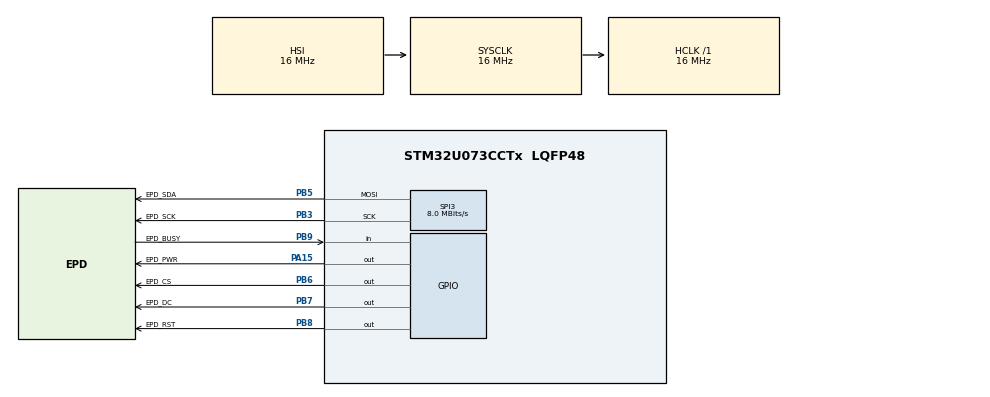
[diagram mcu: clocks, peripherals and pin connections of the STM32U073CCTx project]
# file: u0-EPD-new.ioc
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Mcu.Family=STM32U0
Mcu.Name=STM32U073CCTx
Mcu.Package=LQFP48
NVIC.PriorityGroup=NVIC_PRIORITYGROUP_2
PA13\ (SWDIO).GPIO_Label=SWDIO
PA13\ (SWDIO).Mode=Serial_Wire
PA13\ (SWDIO).Signal=DEBUG_JTMS-SWDIO
PA14\ (SWCLK).GPIO_Label=SWCLK
PA14\ (SWCLK).Mode=Serial_Wire
PA14\ (SWCLK).Signal=DEBUG_JTCK-SWCLK
PA15.GPIO_Label=EPD_PWR
PA15.Signal=GPIO_Output
PB3.GPIO_Label=EPD_SCK
PB3.GPIO_Speed=GPIO_SPEED_FREQ_HIGH
PB3.Mode=TX_Only_Simplex_Unidirect_Master
PB3.Signal=SPI3_SCK
PB5.GPIO_Label=EPD_SDA
PB5.GPIO_Speed=GPIO_SPEED_FREQ_HIGH
PB5.Mode=TX_Only_Simplex_Unidirect_Master
PB5.Signal=SPI3_MOSI
PB6.GPIO_Label=EPD_CS
PB6.Signal=GPIO_Output
PB7.GPIO_Label=EPD_DC
PB7.Signal=GPIO_Output
PB8.GPIO_Label=EPD_RST
PB8.Signal=GPIO_Output
PB9.GPIO_Label=EPD_BUSY
PB9.Signal=GPIO_Input
ProjectManager.HeapSize=0x200
ProjectManager.StackSize=0x400
ProjectManager.TargetToolchain=STM32CubeIDE
RCC.AHBFreq_Value=16000000
RCC.CortexFreq_Value=16000000
RCC.HCLKFreq_Value=16000000
RCC.HSE_VALUE=4000000
RCC.HSI48_VALUE=48000000
RCC.HSI_VALUE=16000000
RCC.LSE_VALUE=32768
RCC.MSI_VALUE=4000000
RCC.SYSCLKFreq_VALUE=16000000
RCC.VCOOutputFreq_Value=64000000
SPI3.BaudRatePrescaler=SPI_BAUDRATEPRESCALER_2
SPI3.CalculateBaudRate=8.0 MBits/s
SPI3.DataSize=SPI_DATASIZE_8BIT
SPI3.Direction=SPI_DIRECTION_2LINES
SPI3.Mode=SPI_MODE_MASTER
SPI3.NSSPMode=SPI_NSS_PULSE_DISABLE
SPI3.VirtualNSS=VM_NSSHARD
SPI3.VirtualType=VM_MASTER
VP_PWR_VS_SECSignals.Mode=Security/Privilege
board=custom

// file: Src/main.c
/* USER CODE BEGIN Header */
/**
  ******************************************************************************
  * @file           : main.c
  * @brief          : Main program body
  ******************************************************************************
  * @attention
  *
  * Copyright (c) 2026 STMicroelectronics.
  * All rights reserved.
  *
  * This software is licensed under terms that can be found in the LICENSE file
  * in the root directory of this software component.
  * If no LICENSE file comes with this software, it is provided AS-IS.
  *
  ******************************************************************************
  */
/* USER CODE END Header */
#include "main.h"

/* USER CODE BEGIN Includes */
#include "GDEY037T03.h"
/* USER CODE END Includes */

SPI_HandleTypeDef hspi3;

void SystemClock_Config(void);
static void MX_GPIO_Init(void);
static void MX_SPI3_Init(void);

int main(void)
{

  /* MCU Configuration--------------------------------------------------------*/

  /* Reset of all peripherals, Initializes the Flash interface and the Systick. */
  HAL_Init();

  /* Configure the system clock */
  SystemClock_Config();

  /* Initialize all configured peripherals */
  MX_GPIO_Init();
  MX_SPI3_Init();
  /* USER CODE BEGIN 2 */
  EPD_wakeup(&hspi3);

  EPD_set_border(&hspi3, BORDER_WHITE);
  EPD_fill_screen(&hspi3, WHITE);
  EPD_refresh(&hspi3);

  EPD_deepsleep(&hspi3);
  /* USER CODE END 2 */

  /* Infinite loop */
  while (1)
  {

  }
}

void SystemClock_Config(void)
{
  RCC_OscInitTypeDef RCC_OscInitStruct = {0};
  RCC_ClkInitTypeDef RCC_ClkInitStruct = {0};

  /** Configure the main internal regulator output voltage
  */
  HAL_PWREx_ControlVoltageScaling(PWR_REGULATOR_VOLTAGE_SCALE2);

  /** Initializes the RCC Oscillators according to the specified parameters
  * in the RCC_OscInitTypeDef structure.
  */
  RCC_OscInitStruct.OscillatorType = RCC_OSCILLATORTYPE_HSI;
  RCC_OscInitStruct.HSIState = RCC_HSI_ON;
  RCC_OscInitStruct.HSICalibrationValue = RCC_HSICALIBRATION_DEFAULT;
  RCC_OscInitStruct.PLL.PLLState = RCC_PLL_NONE;
  if (HAL_RCC_OscConfig(&RCC_OscInitStruct) != HAL_OK)
  {
    Error_Handler();
  }

  /** Initializes the CPU, AHB and APB buses clocks
  */
  RCC_ClkInitStruct.ClockType = RCC_CLOCKTYPE_HCLK|RCC_CLOCKTYPE_SYSCLK
                              |RCC_CLOCKTYPE_PCLK1;
  RCC_ClkInitStruct.SYSCLKSource = RCC_SYSCLKSOURCE_HSI;
  RCC_ClkInitStruct.AHBCLKDivider = RCC_SYSCLK_DIV1;
  RCC_ClkInitStruct.APB1CLKDivider = RCC_HCLK_DIV1;

  if (HAL_RCC_ClockConfig(&RCC_ClkInitStruct, FLASH_LATENCY_1) != HAL_OK)
  {
    Error_Handler();
  }
}

static void MX_SPI3_Init(void)
{

  /* SPI3 parameter configuration*/
  hspi3.Instance = SPI3;
  hspi3.Init.Mode = SPI_MODE_MASTER;
  hspi3.Init.Direction = SPI_DIRECTION_2LINES;
  hspi3.Init.DataSize = SPI_DATASIZE_8BIT;
  hspi3.Init.CLKPolarity = SPI_POLARITY_LOW;
  hspi3.Init.CLKPhase = SPI_PHASE_1EDGE;
  hspi3.Init.NSS = SPI_NSS_SOFT;
  hspi3.Init.BaudRatePrescaler = SPI_BAUDRATEPRESCALER_2;
  hspi3.Init.FirstBit = SPI_FIRSTBIT_MSB;
  hspi3.Init.TIMode = SPI_TIMODE_DISABLE;
  hspi3.Init.CRCCalculation = SPI_CRCCALCULATION_DISABLE;
  hspi3.Init.CRCPolynomial = 7;
  hspi3.Init.CRCLength = SPI_CRC_LENGTH_DATASIZE;
  hspi3.Init.NSSPMode = SPI_NSS_PULSE_DISABLE;
  if (HAL_SPI_Init(&hspi3) != HAL_OK)
  {
    Error_Handler();
  }

}

static void MX_GPIO_Init(void)
{
  GPIO_InitTypeDef GPIO_InitStruct = {0};

  /* GPIO Ports Clock Enable */
  __HAL_RCC_GPIOC_CLK_ENABLE();
  __HAL_RCC_GPIOF_CLK_ENABLE();
  __HAL_RCC_GPIOA_CLK_ENABLE();
  __HAL_RCC_GPIOB_CLK_ENABLE();

  /*Configure GPIO pin Output Level */
  HAL_GPIO_WritePin(EPD_PWR_GPIO_Port, EPD_PWR_Pin, GPIO_PIN_RESET);

  /*Configure GPIO pin Output Level */
  HAL_GPIO_WritePin(GPIOB, EPD_CS_Pin|EPD_DC_Pin|EPD_RST_Pin, GPIO_PIN_RESET);

  /*Configure GPIO pins : PC13 PC14 PC15 */
  GPIO_InitStruct.Pin = GPIO_PIN_13|GPIO_PIN_14|GPIO_PIN_15;
  GPIO_InitStruct.Mode = GPIO_MODE_ANALOG;
  GPIO_InitStruct.Pull = GPIO_NOPULL;
  HAL_GPIO_Init(GPIOC, &GPIO_InitStruct);

  /*Configure GPIO pins : PF0 PF1 PF2 PF3 */
  GPIO_InitStruct.Pin = GPIO_PIN_0|GPIO_PIN_1|GPIO_PIN_2|GPIO_PIN_3;
  GPIO_InitStruct.Mode = GPIO_MODE_ANALOG;
  GPIO_InitStruct.Pull = GPIO_NOPULL;
  HAL_GPIO_Init(GPIOF, &GPIO_InitStruct);

  /*Configure GPIO pins : PA0 PA1 PA2 PA3
                           PA4 PA5 PA6 PA7
                           PA8 PA9 PA10 PA11
                           PA12 */
  GPIO_InitStruct.Pin = GPIO_PIN_0|GPIO_PIN_1|GPIO_PIN_2|GPIO_PIN_3
                          |GPIO_PIN_4|GPIO_PIN_5|GPIO_PIN_6|GPIO_PIN_7
                          |GPIO_PIN_8|GPIO_PIN_9|GPIO_PIN_10|GPIO_PIN_11
                          |GPIO_PIN_12;
  GPIO_InitStruct.Mode = GPIO_MODE_ANALOG;
  GPIO_InitStruct.Pull = GPIO_NOPULL;
  HAL_GPIO_Init(GPIOA, &GPIO_InitStruct);

  /*Configure GPIO pins : PB0 PB1 PB2 PB10
                           PB11 PB12 PB13 PB14
                           PB15 PB4 */
  GPIO_InitStruct.Pin = GPIO_PIN_0|GPIO_PIN_1|GPIO_PIN_2|GPIO_PIN_10
                          |GPIO_PIN_11|GPIO_PIN_12|GPIO_PIN_13|GPIO_PIN_14
                          |GPIO_PIN_15|GPIO_PIN_4;
  GPIO_InitStruct.Mode = GPIO_MODE_ANALOG;
  GPIO_InitStruct.Pull = GPIO_NOPULL;
  HAL_GPIO_Init(GPIOB, &GPIO_InitStruct);

  /*Configure GPIO pin : EPD_PWR_Pin */
  GPIO_InitStruct.Pin = EPD_PWR_Pin;
  GPIO_InitStruct.Mode = GPIO_MODE_OUTPUT_PP;
  GPIO_InitStruct.Pull = GPIO_NOPULL;
  GPIO_InitStruct.Speed = GPIO_SPEED_FREQ_LOW;
  HAL_GPIO_Init(EPD_PWR_GPIO_Port, &GPIO_InitStruct);

  /*Configure GPIO pins : EPD_CS_Pin EPD_DC_Pin EPD_RST_Pin */
  GPIO_InitStruct.Pin = EPD_CS_Pin|EPD_DC_Pin|EPD_RST_Pin;
  GPIO_InitStruct.Mode = GPIO_MODE_OUTPUT_PP;
  GPIO_InitStruct.Pull = GPIO_NOPULL;
  GPIO_InitStruct.Speed = GPIO_SPEED_FREQ_LOW;
  HAL_GPIO_Init(GPIOB, &GPIO_InitStruct);

  /*Configure GPIO pin : EPD_BUSY_Pin */
  GPIO_InitStruct.Pin = EPD_BUSY_Pin;
  GPIO_InitStruct.Mode = GPIO_MODE_INPUT;
  GPIO_InitStruct.Pull = GPIO_NOPULL;
  HAL_GPIO_Init(EPD_BUSY_GPIO_Port, &GPIO_InitStruct);

}

void Error_Handler(void)
{
  __disable_irq();
  while (1)
  {
  }
}
